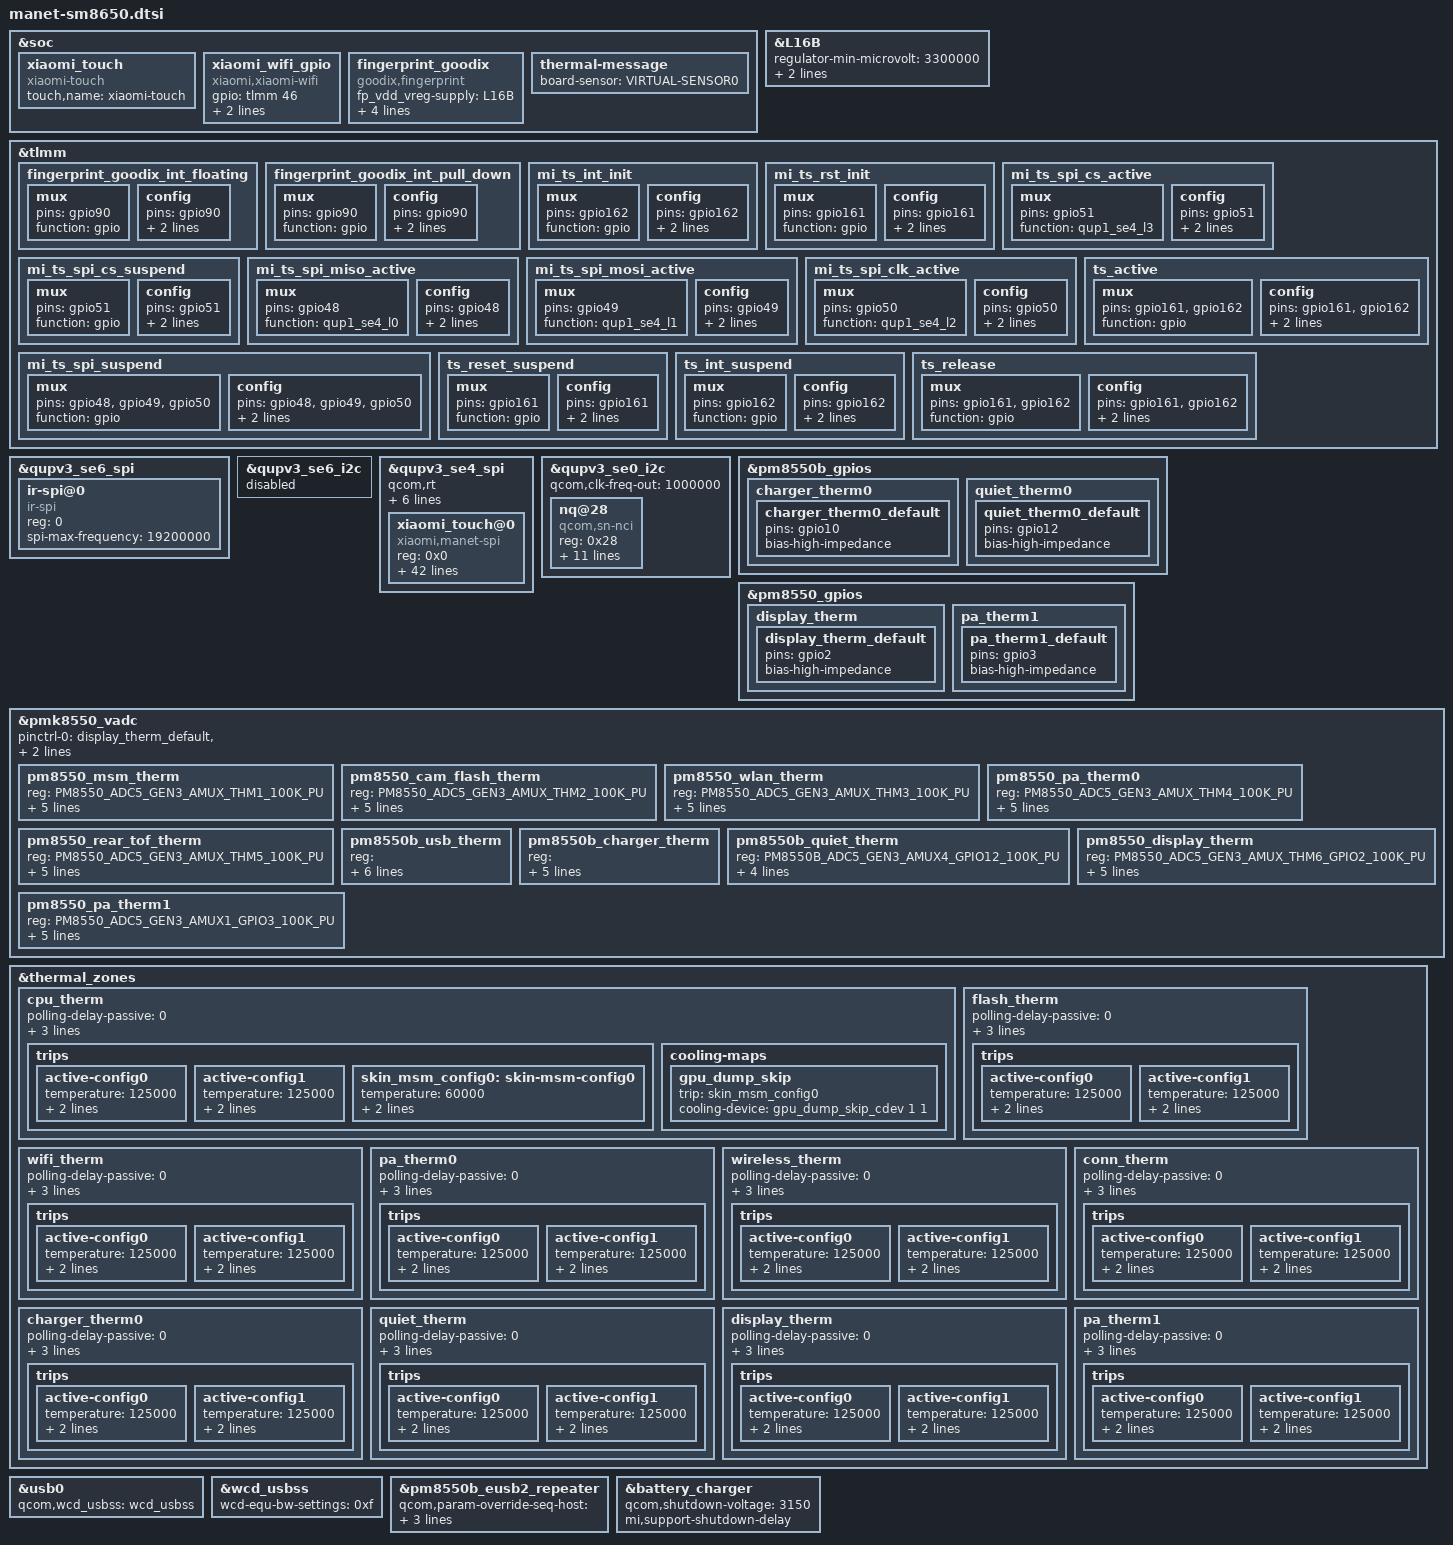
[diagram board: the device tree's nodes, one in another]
/*
  this file is for attribution only of manet
  And public attribution of xiaomi platforms(like N11U and so and)
*/
#define MANET_REGULATOR_OCP
#include "manet-pinctrl.dtsi"
#include "xiaomi-sm8650-common.dtsi"

&soc {
	xiaomi_touch {
		compatible = "xiaomi-touch";
		status = "ok";
		touch,name = "xiaomi-touch";
	};

	xiaomi_wifi_gpio {
		compatible = "xiaomi,xiaomi-wifi";
		gpio = <&tlmm 46 0x00>;
		debounce-time = <30>;
		pinctrl-names = "default";
		pinctrl-0 = <&wifi_ctrl_irq>;
		status = "ok";
	};

	fingerprint_goodix {
		compatible = "goodix,fingerprint";
		fp_vdd_vreg-supply = <&L16B>;
		goodix,gpio-reset = <&tlmm 89 0x0>;
		goodix,gpio-irq = <&tlmm 90 0x0>;
		pinctrl-names = "fingerprint_goodix_default", "fingerprint_goodix_rst";
		pinctrl-0 = <&fingerprint_goodix_int_floating>;
		pinctrl-1 = <&fingerprint_goodix_int_pull_down>;
		status = "ok";
	};
};

&L16B {
	regulator-min-microvolt = <3300000>;
	regulator-max-microvolt = <3300000>;
	qcom,init-voltage = <3300000>;
};

&tlmm {
	fingerprint_goodix_int_floating: fingerprint_goodix_int_floating {
		mux {
			pins = "gpio90";
			function = "gpio";
		};
		config {
			pins = "gpio90";
			input-enable;
			bias-disable;
		};
	};
	fingerprint_goodix_int_pull_down: fingerprint_goodix_int_pull_down {
		mux {
			pins = "gpio90";
			function = "gpio";
		};
		config {
			pins = "gpio90";
			input-enable;
			bias-pull-down;
		};
	};
	mi_ts_int_init: mi_ts_int_init {
		mux {
			pins = "gpio162";
			function = "gpio";
		};

		config {
			pins = "gpio162";
			drive-strength = <8>;
			bias-pull-up;
		};
	};
	mi_ts_rst_init: mi_ts_rst_init {
		mux {
			pins = "gpio161";
			function = "gpio";
		};

		config {
			pins = "gpio161";
			drive-strength = <8>;
			bias-pull-up;
		};
	};

	mi_ts_spi_cs_active: mi_ts_spi_cs_active {
		mux {
			pins = "gpio51";
			function = "qup1_se4_l3";
		};

		config {
			pins = "gpio51";
			drive-strength = <16>;
			bias-pull-up;
		};
	};

	mi_ts_spi_cs_suspend: mi_ts_spi_cs_suspend {
		mux {
			pins = "gpio51";
			function = "gpio";
		};

		config {
			pins = "gpio51";
			drive-strength = <16>;
			bias-pull-up;
		};
	};

	mi_ts_spi_miso_active: mi_ts_spi_miso_active {
		mux {
			pins = "gpio48";
			function = "qup1_se4_l0";
		};
		config {
			pins = "gpio48";
			drive-strength = <6>;
			bias-disable;
		};
	};

	mi_ts_spi_mosi_active: mi_ts_spi_mosi_active {
		mux {
			pins = "gpio49";
			function = "qup1_se4_l1";
		};
		config {
			pins = "gpio49";
			drive-strength = <6>;
			bias-disable;
		};
	};

	mi_ts_spi_clk_active: mi_ts_spi_clk_active {
		mux {
			pins = "gpio50";
			function = "qup1_se4_l2";
		};
		config {
			pins = "gpio50";
			drive-strength = <6>;
			bias-disable;
		};
	};

	mi_ts_spi_suspend: mi_ts_spi_suspend {
		mux {
			pins = "gpio48", "gpio49", "gpio50";
			function = "gpio";
		};

		config {
			pins = "gpio48", "gpio49", "gpio50";
			drive-strength = <6>;
			bias-disable;
		};
	};

	ts_active: ts_active {
		mux {
			pins = "gpio161", "gpio162";
			function = "gpio";
		};

		config {
			pins = "gpio161", "gpio162";
			drive-strength = <8>;
			bias-pull-up;
		};
	};

	ts_reset_suspend: ts_reset_suspend {
		mux {
			pins = "gpio161";
			function = "gpio";
		};

		config {
			pins = "gpio161";
			drive-strength = <2>;
			bias-pull-down;
		};
	};

	ts_int_suspend: ts_int_suspend {
		mux {
			pins = "gpio162";
			function = "gpio";
		};

		config {
			pins = "gpio162";
			drive-strength = <2>;
			bias-pull-down;
		};
	};

	ts_release: ts_release {
		mux {
			pins = "gpio161", "gpio162";
			function = "gpio";
		};

		config {
			pins = "gpio161", "gpio162";
			drive-strength = <2>;
			bias-disable;
		};
	};
};

&qupv3_se6_spi {
	status = "ok";
	ir-spi@0 {
		compatible = "ir-spi";
		reg = <0>;
		spi-max-frequency = <19200000>;
		status = "ok";
	};
};

&qupv3_se6_i2c {
	status = "disabled";
};

&qupv3_se4_spi {
	status = "ok";
	qcom,rt;
	qcom,la-vm;
	pinctrl-0 = <&mi_ts_spi_mosi_active>, <&mi_ts_spi_miso_active>,
		    <&mi_ts_spi_clk_active>, <&mi_ts_spi_cs_active>;
	pinctrl-1 = <&mi_ts_spi_suspend>, <&mi_ts_spi_cs_suspend>;
	xiaomi_touch@0 {
		status = "ok";
		compatible = "xiaomi,manet-spi";
		reg = <0x0>;
		spi-max-frequency = <15000000>;
		interrupt-parent = <&tlmm>;
		interrupts = <162 0x2008>;
		pinctrl-names = "pmx_ts_active", "pmx_ts_suspend";
		pinctrl-0 = <&mi_ts_int_init &mi_ts_rst_init>;
		pinctrl-1 = <&ts_int_suspend &ts_reset_suspend>;

		//goodix,avdd-gpio = <&tlmm 164 0x0>;
		goodix,avdd-name = "avdd";
		avdd-supply = <&L14B>;

		goodix,iovdd-name = "vdd";
		vdd-supply = <&L12B>;
		goodix,irq-gpio = <&tlmm 162 0x2008>;
		goodix,reset-gpio = <&tlmm 161 0x00>;
		goodix,irq-flags = <2>;
		goodix,panel-max-x = <143999>;
		goodix,panel-max-y = <319999>;
		goodix,super-resolution-factor = <100>;
		goodix,panel-max-w = <255>;
		goodix,panel-max-p = <4096>;
		goodix,firmware-name = "goodix_firmware_manet";
		goodix,config-name = "goodix_cfg_group_manet";
		goodix,touch-expert-array = <2 3 2 2
					     4 3 3 2
					     3 3 4 2>;
		mi_tp,game-mode-array =
				<1 0 0 0 0>;  /* MAX MIN DEF SET GET	*/
		mi_tp,active-mode-array =
				<1 0 0 0 0>;  /* MAX MIN DEF SET GET	*/
		mi_tp,tolerance-array =
				<4 0 2 2 2>;  /* MAX MIN DEF SET GET	*/
		mi_tp,up-threshold-array =
				<4 0 3 3 3>;  /* MAX MIN DEF SET GET	*/
		mi_tp,aim-sensitivity-array =
				<4 0 2 2 2>;  /* MAX MIN DEF SET GET	*/
		mi_tp,tap-stability-array =
				<4 0 2 2 2>;  /* MAX MIN DEF SET GET	*/
		mi_tp,edge-filter-array =
				<3 0 2 2 2>;  /* MAX MIN DEF SET GET	*/
		mi_tp,panel-orien-array =
				<3 0 0 0 0>;  /* MAX MIN DEF SET GET	*/
		mi_tp,report-rate-array =
				<3 0 0 0 0>;  /* MAX MIN DEF SET GET	*/
		mi_tp,expert-mode-array =
				<3 1 1 1 1>;  /* MAX MIN DEF SET GET	*/
		goodix,qts_en;
		goodix,touch-type = "primary";
		qts,trusted-touch-mode = "vm_mode";
		qts,touch-environment = "tvm";
		qts,trusted-touch-type = "primary";
		qts,trusted-touch-spi-irq = <598>;
		qts,trusted-touch-io-bases = <0xa90000 0xa10000>;
		qts,trusted-touch-io-sizes = <0x1000 0x4000>;
		qts,trusted-touch-vm-gpio-list = <&tlmm 48 0 &tlmm 49 0 &tlmm 50 0
						&tlmm 51 0 &tlmm 161 0 &tlmm 162 0x2008>;
	};
};

&qupv3_se0_i2c {
	status = "ok";
	qcom,clk-freq-out = <1000000>;
	#address-cells = <1>;
	#size-cells = <0>;
	nq@28 {
		compatible = "qcom,sn-nci";
		reg = <0x28>;
		qcom,sn-irq = <&tlmm 75 0x00>;
		qcom,sn-ven = <&tlmm 34 0x00>;
		qcom,sn-clkreq = <&tlmm 35 0x00>;
		qcom,sn-szone = "enable";
		qcom,sn-vdd-1p8-supply = <&L3C>;
		qcom,sn-vdd-1p8-voltage = <1200000 1200000>;
		qcom,sn-vdd-1p8-current = <157000>;
		interrupt-parent = <&tlmm>;
		interrupts = <75 0>;
		interrupt-names = "nfc_irq";
		pinctrl-names = "nfc_active", "nfc_suspend";
		pinctrl-0 = <&nfc_int_active &nfc_enable_active>;
		pinctrl-1 = <&nfc_int_suspend &nfc_enable_suspend>;
	};
};

&pm8550b_gpios {
	charger_therm0 {
		charger_therm0_default: charger_therm0_default {
		pins = "gpio10";
		bias-high-impedance;
		};
	};
};

&pm8550b_gpios {
	quiet_therm0 {
		quiet_therm0_default: quiet_therm0_default {
		pins = "gpio12";
		bias-high-impedance;
		};
	};
};

&pm8550_gpios {
	display_therm {
		display_therm_default: display_therm_default {
		pins = "gpio2";
		bias-high-impedance;
		};
	};
};

&pm8550_gpios {
	pa_therm1 {
		pa_therm1_default: pa_therm1_default {
		pins = "gpio3";
		bias-high-impedance;
		};
	};
};

&pmk8550_vadc {
	pinctrl-names = "default";
	pinctrl-0 = <&display_therm_default>, <&charger_therm0_default>,<&pa_therm1_default>,<&quiet_therm0_default>;

	pm8550_msm_therm {
		reg = <PM8550_ADC5_GEN3_AMUX_THM1_100K_PU>;
		label = "pm8550_msm_therm";
		qcom,ratiometric;
		qcom,hw-settle-time = <200>;
		qcom,pre-scaling = <1 1>;
		qcom,adc-tm-type = <1>;
	};

	pm8550_cam_flash_therm {
		reg = <PM8550_ADC5_GEN3_AMUX_THM2_100K_PU>;
		label = "pm8550_cam_flash_therm";
		qcom,ratiometric;
		qcom,hw-settle-time = <200>;
		qcom,pre-scaling = <1 1>;
		qcom,adc-tm-type = <1>;
	};

	pm8550_wlan_therm {
		reg = <PM8550_ADC5_GEN3_AMUX_THM3_100K_PU>;
		label = "pm8550_wlan_therm";
		qcom,ratiometric;
		qcom,hw-settle-time = <200>;
		qcom,pre-scaling = <1 1>;
		qcom,adc-tm-type = <1>;
	};

	pm8550_pa_therm0 {
		reg = <PM8550_ADC5_GEN3_AMUX_THM4_100K_PU>;
		label = "pm8550_pa_therm_0";
		qcom,ratiometric;
		qcom,hw-settle-time = <200>;
		qcom,pre-scaling = <1 1>;
		qcom,adc-tm-type = <1>;
	};

	pm8550_rear_tof_therm {
		reg = <PM8550_ADC5_GEN3_AMUX_THM5_100K_PU>;
		label = "pm8550_rear_tof_therm";
		qcom,ratiometric;
		qcom,hw-settle-time = <200>;
		qcom,pre-scaling = <1 1>;
		qcom,adc-tm-type = <1>;
	};

	pm8550b_usb_therm {
		reg = <PM8550B_ADC5_GEN3_AMUX_THM4_USB_THERM_100K_PU>;
		label = "pm8550b_usb_therm";
		qcom,ratiometric;
		qcom,hw-settle-time = <200>;
		qcom,pre-scaling = <1 1>;
		qcom,adc-tm-type = <1>;
	};

	pm8550b_charger_therm {
		reg = <PM8550B_ADC5_GEN3_AMUX_THM6_GPIO10_100K_PU>;
		label = "pm8550b_charger_therm";
		qcom,ratiometric;
		qcom,pre-scaling = <1 1>;
		qcom,adc-tm-type = <1>;
	};

	pm8550b_quiet_therm {
 		reg = <PM8550B_ADC5_GEN3_AMUX4_GPIO12_100K_PU>;
		label = "pm8550b_quiet_therm";
		qcom,ratiometric;
		qcom,pre-scaling = <1 1>;
		qcom,adc-tm-type = <1>;
        };

	pm8550_display_therm {
 		reg = <PM8550_ADC5_GEN3_AMUX_THM6_GPIO2_100K_PU>;
 		label = "pm8550_display_therm";
 		qcom,ratiometric;
 		qcom,hw-settle-time = <200>;
 		qcom,pre-scaling = <1 1>;
 		qcom,adc-tm-type = <1>;
 	};

	pm8550_pa_therm1 {
 		reg = <PM8550_ADC5_GEN3_AMUX1_GPIO3_100K_PU>;
 		label = "pm8550_pa_therm1";
 		qcom,ratiometric;
 		qcom,hw-settle-time = <200>;
 		qcom,pre-scaling = <1 1>;
 		qcom,adc-tm-type = <1>;
 	};
};

&thermal_zones {
	cpu_therm {
		polling-delay-passive = <0>;
		polling-delay = <0>;
		thermal-sensors = <&pmk8550_vadc PM8550_ADC5_GEN3_AMUX_THM1_100K_PU>;
		trips {
			active-config0 {
				temperature = <125000>;
				hysteresis = <1000>;
				type = "passive";
			};

			active-config1 {
				temperature = <125000>;
				hysteresis = <1000>;
				type = "passive";
			};

			skin_msm_config0: skin-msm-config0 {
				temperature = <60000>;
				hysteresis = <10000>;
				type = "passive";
			};
		};
		cooling-maps {
			gpu_dump_skip {
				trip = <&skin_msm_config0>;
				cooling-device = <&gpu_dump_skip_cdev 1 1>;
			};
		};
	};

	flash_therm {
		polling-delay-passive = <0>;
		polling-delay = <0>;
		thermal-sensors = <&pmk8550_vadc PM8550_ADC5_GEN3_AMUX_THM2_100K_PU>;
		trips {
			active-config0 {
				temperature = <125000>;
				hysteresis = <1000>;
				type = "passive";
			};

			active-config1 {
				temperature = <125000>;
				hysteresis = <1000>;
				type = "passive";
			};
		};
	};

	wifi_therm {
		polling-delay-passive = <0>;
		polling-delay = <0>;
		thermal-sensors = <&pmk8550_vadc PM8550_ADC5_GEN3_AMUX_THM3_100K_PU>;
		trips {
			active-config0 {
				temperature = <125000>;
				hysteresis = <1000>;
				type = "passive";
			};

			active-config1 {
				temperature = <125000>;
				hysteresis = <1000>;
				type = "passive";
			};
		};
	};

	pa_therm0 {
		polling-delay-passive = <0>;
		polling-delay = <0>;
		thermal-sensors = <&pmk8550_vadc PM8550_ADC5_GEN3_AMUX_THM4_100K_PU>;
		trips {
			active-config0 {
				temperature = <125000>;
				hysteresis = <1000>;
				type = "passive";
			};

			active-config1 {
				temperature = <125000>;
				hysteresis = <1000>;
				type = "passive";
			};
		};
	};

	wireless_therm {
		polling-delay-passive = <0>;
		polling-delay = <0>;
		thermal-sensors = <&pmk8550_vadc PM8550_ADC5_GEN3_AMUX_THM5_100K_PU>;
		trips {
			active-config0 {
				temperature = <125000>;
				hysteresis = <1000>;
				type = "passive";
			};

			active-config1 {
				temperature = <125000>;
				hysteresis = <1000>;
				type = "passive";
			};
		};
	};

	conn_therm {
		polling-delay-passive = <0>;
		polling-delay = <0>;
		thermal-sensors = <&pmk8550_vadc PM8550B_ADC5_GEN3_AMUX_THM4_USB_THERM_100K_PU>;
		trips {
			active-config0 {
				temperature = <125000>;
				hysteresis = <1000>;
				type = "passive";
			};

			active-config1 {
				temperature = <125000>;
				hysteresis = <1000>;
				type = "passive";
			};
		};
	};

	charger_therm0 {
		polling-delay-passive = <0>;
		polling-delay = <0>;
		thermal-sensors = <&pmk8550_vadc PM8550B_ADC5_GEN3_AMUX_THM6_GPIO10_100K_PU>;
		trips {
			active-config0 {
				temperature = <125000>;
				hysteresis = <1000>;
				type = "passive";
			};

			active-config1 {
				temperature = <125000>;
				hysteresis = <1000>;
				type = "passive";
			};
		};
	};

	quiet_therm {
		polling-delay-passive = <0>;
		polling-delay = <0>;
		thermal-sensors = <&pmk8550_vadc PM8550B_ADC5_GEN3_AMUX4_GPIO12_100K_PU>;
		trips {
			active-config0 {
				temperature = <125000>;
				hysteresis = <1000>;
				type = "passive";
			};
			active-config1 {
				temperature = <125000>;
				hysteresis = <1000>;
				type = "passive";
			};
		};
	};

	display_therm {
		polling-delay-passive = <0>;
		polling-delay = <0>;
		thermal-sensors = <&pmk8550_vadc PM8550_ADC5_GEN3_AMUX_THM6_GPIO2_100K_PU>;
		trips {
			active-config0 {
				temperature = <125000>;
				hysteresis = <1000>;
				type = "passive";
			};
			active-config1 {
				temperature = <125000>;
				hysteresis = <1000>;
				type = "passive";
			};
		};
	};

	pa_therm1 {
		polling-delay-passive = <0>;
		polling-delay = <0>;
		thermal-sensors = <&pmk8550_vadc PM8550_ADC5_GEN3_AMUX1_GPIO3_100K_PU>;
		trips {
			active-config0 {
				temperature = <125000>;
				hysteresis = <1000>;
				type = "passive";
			};
			active-config1 {
				temperature = <125000>;
				hysteresis = <1000>;
				type = "passive";
			};
		};
	};
};

&soc {
	thermal-message {
 		board-sensor = "VIRTUAL-SENSOR0";
	};
};

&usb0 {
	qcom,wcd_usbss = <&wcd_usbss>;
};

&wcd_usbss {
	wcd-equ-bw-settings = <0xf>;
};

&pm8550b_eusb2_repeater {
	qcom,param-override-seq-host =
		<0x00 0x50
		0x06 0x51
		0x01 0x52
		0x07 0x53
		0x03 0x54
		0x00 0x55
		0x00 0x56
		0x04 0x57
		0x02 0x58
		0x03 0x59
		0x01 0x5a
		0x02 0x5b>;
	qcom,param-override-seq =
		<0x00 0x50
		0x0F 0x51
		0x04 0x52
		0x07 0x53
		0x03 0x54
		0x01 0x55
		0x00 0x56
		0x07 0x57
		0x02 0x58
		0x03 0x59
		0x01 0x5a
		0x02 0x5b>;
};

&battery_charger {
	qcom,shutdown-voltage = <3150>;
	mi,support-shutdown-delay;
};
